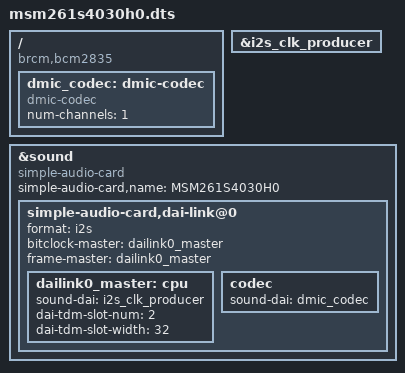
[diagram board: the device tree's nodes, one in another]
// Device Tree Overlay — MSM261S4030H0R I2S MEMS Microphone
// AutoChair / Raspberry Pi 4 — Audio Phase 2
//
// This overlay configures the Raspberry Pi 4's bcm2835 I2S controller
// as the bit-clock and frame-clock master for the DFRobot I2S MEMS
// microphone (MSM261S4030H0R, SKU: SEN0526).
//
// I2S protocol parameters (confirmed from MSM261S4030H0 datasheet and
// verified by successful capture on physical hardware):
//   - 2 TDM slots (stereo I2S frame)
//   - 32-bit slot width
//   - 24-bit audio data packed in 32-bit words
//   - Nominal SCK = 3.072 MHz (48 kHz × 64 cycles/frame)
//   - WS / frame-sync = 48 kHz
//   - Pi I2S controller is both bit-clock master and frame-clock master
//
// Wiring (verified on Raspberry Pi 4 Model B Rev 1.5):
//   VDD -> physical pin 1  (3.3V)
//   GND -> physical pin 6  (GND)
//   SCK -> physical pin 12 (GPIO18 / PCM_CLK)
//   WS  -> physical pin 35 (GPIO19 / PCM_FS)
//   SD  -> physical pin 38 (GPIO20 / PCM_DIN)
//   L/R -> physical pin 39 (GND)  ← selects LEFT channel
//
// Hardware status:
//   HARDWARE_INTEGRATED — verified on Raspberry Pi 4 Model B Rev 1.5
//   ALSA capture confirmed: card 3: MSM261S4030H0, device 0
//   Audible voice recording verified (5 s, 48 kHz, S32_LE, stereo)
//
// Compiled and installed as:
//   /boot/firmware/overlays/msm261s4030h0.dtbo
// Enabled in /boot/firmware/config.txt with:
//   dtoverlay=msm261s4030h0

/dts-v1/;
/plugin/;

/ {
    compatible = "brcm,bcm2835";

    fragment@0 {
        target = <&i2s_clk_producer>;
        __overlay__ {
            status = "okay";
        };
    };

    fragment@1 {
        target-path = "/";
        __overlay__ {
            dmic_codec: dmic-codec {
                #sound-dai-cells = <0>;
                compatible = "dmic-codec";
                num-channels = <1>;
            };
        };
    };

    fragment@2 {
        target = <&sound>;
        __overlay__ {
            compatible = "simple-audio-card";
            simple-audio-card,name = "MSM261S4030H0";
            status = "okay";

            simple-audio-card,dai-link@0 {
                format = "i2s";
                bitclock-master = <&dailink0_master>;
                frame-master = <&dailink0_master>;

                dailink0_master: cpu {
                    sound-dai = <&i2s_clk_producer>;
                    dai-tdm-slot-num = <2>;
                    dai-tdm-slot-width = <32>;
                };

                codec {
                    sound-dai = <&dmic_codec>;
                };
            };
        };
    };
};
